# STM32U3B5xx register map
File version: 1.0
Registers are 32-bit, read-write, reset 0x0 unless marked. A register's access mark holds for its fields unless they carry their own. Offsets are from the block's base; [hi:lo] are bit positions; {n}, {i} and the like mark numbered series.

## PWR — Power Control
Base 0x40030800
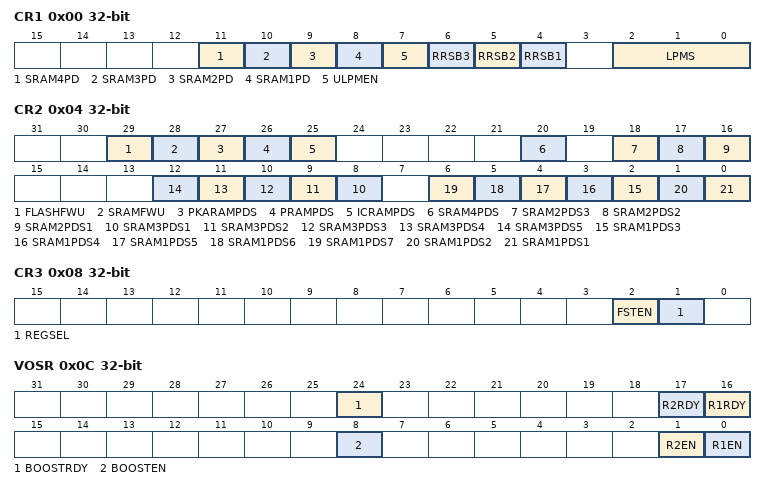
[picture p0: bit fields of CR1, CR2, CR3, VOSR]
0x00 CR1 — Power control register 1
  [11] SRAM4PD — SRAM4 (64 KB) power-down in Run mode
  [10] SRAM3PD — SRAM3 (320 KB) power-down in Run mode
  [9] SRAM2PD — SRAM2 (64 KB) power-down in Run mode
  [8] SRAM1PD — SRAM1 (192 KB) power-down in Run mode
  [7] ULPMEN — BOR ultra-low power mode in Standby/Shutdown
  [6] RRSB3 — SRAM2 page 3 Retention in Standby
  [5] RRSB2 — SRAM2 page 2 Retention in Standby
  [4] RRSB1 — SRAM2 page 1 Retention in Standby
  [2:0] LPMS — LPMS[2:0] Low-power mode selection field
    {v}=STOP{v} (Stop {v} mode) (v=0..3); 4=STANDBY (Standby mode); 6=SHUTDOWN (Shutdown mode)
0x04 CR2 — Power control register 2
  [29] FLASHFWU — Flash memory fast wakeup from Stop modes (Stop 0, 1)
  [28] SRAMFWU — SRAM fast wakeup from Stop modes (Stop 0, 1)
  [27] PKARAMPDS — PKA32 SRAM power-down in Stop modes (Stop 0, 1)
    0=NO_RETENTION (PKA SRAM no retention in Stop modes (Stop 0, 1, 2, 3)); 1=RETENTION
  [26] PRAMPDS — FDCAN and USB peripherals SRAM power-down in Stop modes (Stop 0, 1, 2, 3)
    0=NO_RETENTION; 1=RETENTION
  [25] ICRAMPDS — ICACHE SRAM power-down in Stop modes (Stop 0, 1, 2, 3)
    0=NO_RETENTION; 1=RETENTION
  [20] SRAM4PDS — SRAM4 (64 KB) power-down in Stop modes (Stop 0, 1, 2, 3)
  [18] SRAM2PDS3 — SRAM2 page 3 (32 KB) power-down in Stop modes (Stop 0, 1, 2, 3)
  [17] SRAM2PDS2 — SRAM2 page 2 (24 KB) power-down in Stop modes (Stop 0, 1, 2, 3)
  [16] SRAM2PDS1 — SRAM2 page 1 (8 KB) power-down in Stop modes (Stop 0, 1, 2, 3)
  [n+7] SRAM3PDS{n} (n=1..5) — SRAM3 page {n} (64 KB) power-down in Stop modes (Stop 0, 1, 2, 3)
  [n-1] SRAM1PDS{n} (n=3..7) — SRAM1 page {n} (32 KB) power-down in Stop modes (Stop 0, 1, 2, 3)
  [1] SRAM1PDS2 — SRAM1 page 2 (16 KB) power-down in Stop modes (Stop 0, 1, 2, 3)
  [0] SRAM1PDS1 — SRAM1 page 1 (16 KB) power-down in Stop modes (Stop 0, 1, 2, 3)
0x08 CR3 — Power control register 3
  [2] FSTEN — Fast soft start
  [1] REGSEL — Regulator selection
    0=LDO_SUPPLY (LDO regulator supply); 1=SMPS_SUPPLY (SMPS regulator supply)
0x0C VOSR — Power voltage scaling register
  [24] BOOSTRDY — EPOD booster ready
  [17] R2RDY — Ready bit for Vcore range 2 selection
  [16] R1RDY — Ready bit for Vcore range 1 selection
  [8] BOOSTEN — EPOD booster enable
  [1] R2EN — Voltage scaling range 2 selection
  [0] R1EN — Voltage scaling range 1 selection
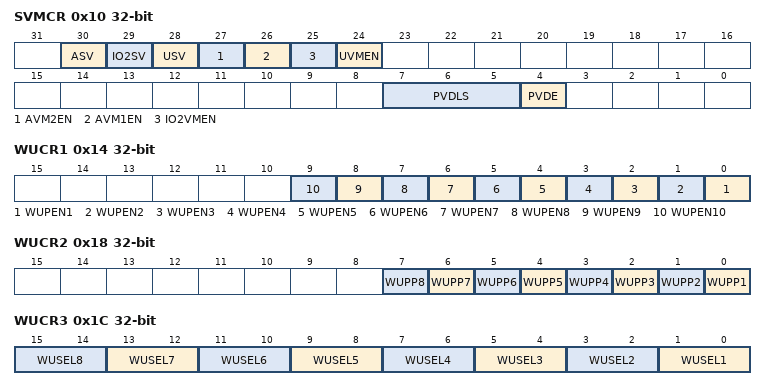
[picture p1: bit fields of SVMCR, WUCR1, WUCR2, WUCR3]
0x10 SVMCR — Power supply voltage monitoring control register
  [30] ASV — VDDA Independent analog supply valid
  [29] IO2SV — VDDIO2 Independent I/Os supply valid
  [28] USV — VDDUSB Independent USB supply valid
  [27] AVM2EN — VDDA Independent analog supply voltage monitor 2 enable
  [26] AVM1EN — VDDA Independent analog supply voltage monitor 1 enable
  [25] IO2VMEN — VDDIO2 Independent I/Os voltage monitor enable
  [24] UVMEN — VDDUSB Independent USB supply voltage monitor enable
  [7:5] PVDLS — PVDLS[2:0] Programmable voltage detector level selection field
    0=PVDLEVEL_0 (Voltage threshold detected by PVD 2.0 V); 1=PVDLEVEL_1 (Voltage threshold detected by PVD 2.2 V); 2=PVDLEVEL_2 (Voltage threshold detected by PVD 2.4 V); 3=PVDLEVEL_3 (Voltage threshold detected by PVD 2.5 V); 4=PVDLEVEL_4 (Voltage threshold detected by PVD 2.6 V); 5=PVDLEVEL_5 (Voltage threshold detected by PVD 2.8 V); 6=PVDLEVEL_6 (Voltage threshold detected by PVD 2.9 V); 7=PVDLEVEL_7
  [4] PVDE — Programmable voltage detector enable
0x14 WUCR1 — Power wakeup control register 1
  [n-1] WUPEN{n} (n=1..10) — Wakeup line WKUP{n} enable
0x18 WUCR2 — Power wakeup control register 2
  [n-1] WUPP{n} (n=1..8) — Wakeup line WKUP{n} polarity
0x1C WUCR3 — Power wakeup control register 3
  [2n-1:2n-2] WUSEL{n} (n=1..8) — Wakeup line WKUP{n} selection field
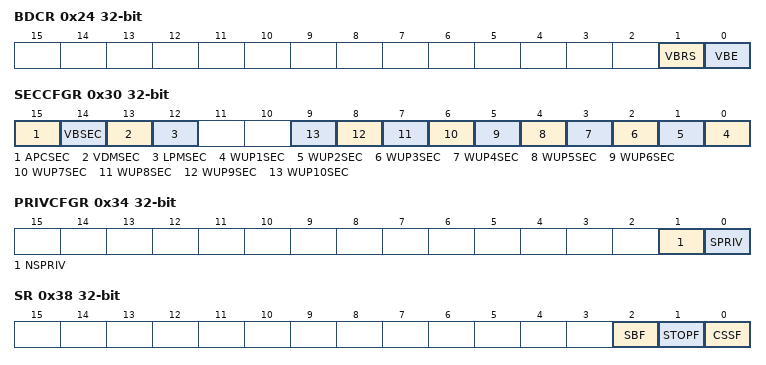
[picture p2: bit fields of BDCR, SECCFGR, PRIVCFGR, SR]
0x24 BDCR — Power backup domain control register
  [1] VBRS — VBAT charging resistor selection
    0=RESISTOR_5K (Charge the battery through a 5 kO resistor); 1=RESISTOR_1_5K (Charge the battery through a 1.5 kO resistor)
  [0] VBE — VBAT charging enable
0x28 DBPR — Power disable backup domain register
  [0] DBP — Disable backup domain write protection
0x30 SECCFGR — Power Security configuration register
  [15] APCSEC — Pull-up/pull-down secure protection
  [14] VBSEC — Backup domain secure protection
  [13] VDMSEC — Voltage detection and monitoring secure protection
  [12] LPMSEC — Low-power modes secure protection
  [n-1] WUP{n}SEC (n=1..10) — WUP{n} secure protection
0x34 PRIVCFGR — Power privilege control register
  [1] NSPRIV — PWR non-secure functions privilege configuration
  [0] SPRIV — PWR secure functions privilege configuration
0x38 SR — Power status register
  [2] SBF — Standby flag
  [1] STOPF — Stop flag
  [0] CSSF — Clear Stop and Standby/Shutdown flags
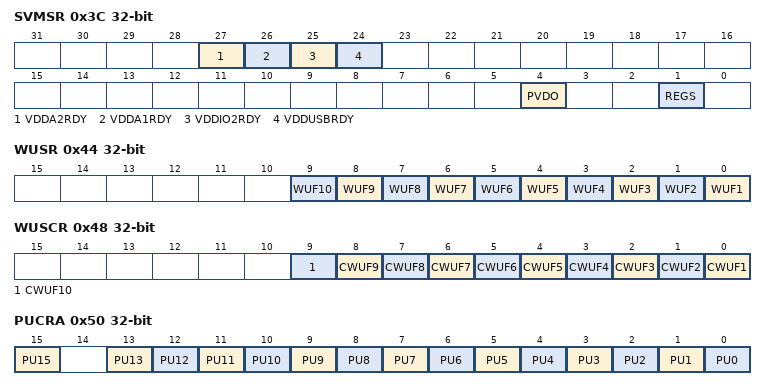
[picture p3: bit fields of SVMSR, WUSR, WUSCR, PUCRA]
0x3C SVMSR — Power supply voltage monitoring status register
  [27] VDDA2RDY — VDDA ready versus 1.8V voltage monitor
  [26] VDDA1RDY — VDDA ready versus 1.6V voltage monitor
  [25] VDDIO2RDY — VDDIO2 ready
  [24] VDDUSBRDY — VDDUSB ready
  [4] PVDO — VDD voltage detector output
  [1] REGS — Regulator status
0x44 WUSR — Power wakeup status register
  [n-1] WUF{n} (n=1..10) — Wakeup flag {n}
0x48 WUSCR — Power wakeup status clear register
  [n-1] CWUF{n} (n=1..10) — Wakeup clear flag {n}
0x4C APCR — Power apply pull configuration register
  [0] APC — Apply pull-up and pull-down configuration
0x50 PUCRA — Power Port A pull-up control register
  [15] PU15 — Apply pull-up for PA15
  [n] PU{n} (n=0..13) — Apply pull-up for PA{n}
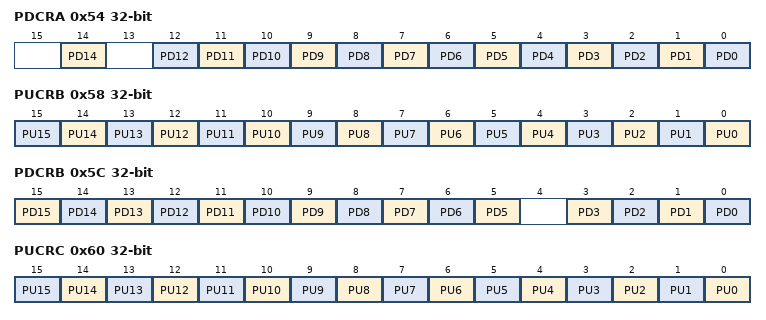
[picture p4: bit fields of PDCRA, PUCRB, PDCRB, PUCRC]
0x54 PDCRA — Power Port A pull-down control register
  [14] PD14 — Apply pull-down for PA14
  [n] PD{n} (n=0..12) — Apply pull-down for PA{n}
0x58 PUCRB — Power Port B pull-up control register
  [n] PU{n} (n=0..15) — Apply pull-up for PB{n}
0x5C PDCRB — Power Port B pull-down control register
  [n] PD{n} (n=5..15) — Apply pull-down for PB{n}
  [n] PD{n} (n=0..3) — Apply pull-down for PB{n}
0x60 PUCRC — Power Port C pull-up control register
  [n] PU{n} (n=0..15) — Apply pull-up for PC{n}
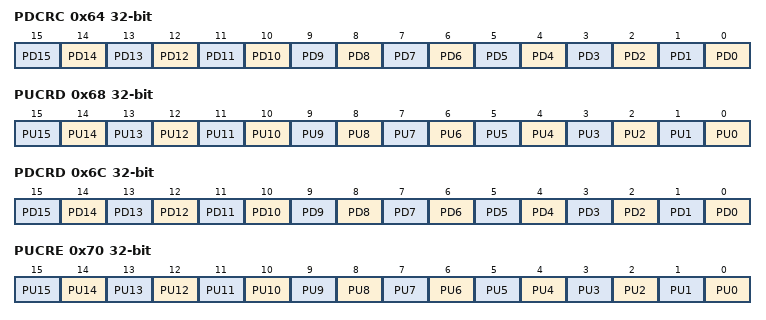
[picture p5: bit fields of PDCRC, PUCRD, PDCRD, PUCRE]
0x64 PDCRC — Power Port C pull-down control register
  [n] PD{n} (n=0..15) — Apply pull-down for PC{n}
0x68 PUCRD — Power Port D pull-up control register
  [n] PU{n} (n=0..15) — Apply pull-up for PD{n}
0x6C PDCRD — Power Port D pull-down control register
  [n] PD{n} (n=0..15) — Apply pull-down for PD{n}
0x70 PUCRE — Power Port E pull-up control register
  [n] PU{n} (n=0..15) — Apply pull-up for PE{n}
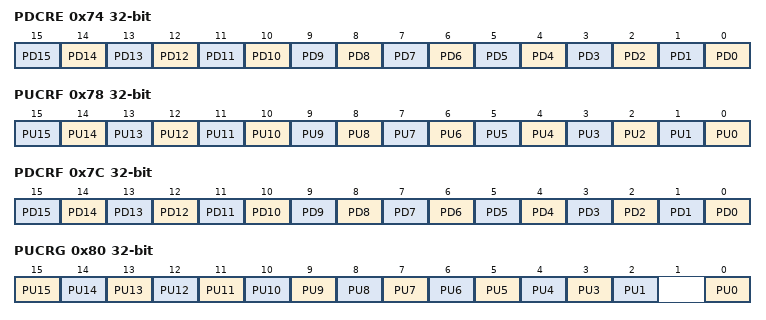
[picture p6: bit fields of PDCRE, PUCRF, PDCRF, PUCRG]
0x74 PDCRE — Power Port E pull-down control register
  [n] PD{n} (n=0..15) — Apply pull-down for PE{n}
0x78 PUCRF — Power Port F pull-up control register
  [n] PU{n} (n=0..15) — Apply pull-up for PF{n}
0x7C PDCRF — Power Port F pull-down control register
  [n] PD{n} (n=0..15) — Apply pull-down for PF{n}
0x80 PUCRG — Power Port G pull-up control register
  [n] PU{n} (n=3..15) — Apply pull-up for PG{n}
  [2] PU1 — Apply pull-up for PG1
  [0] PU0 — Apply pull-up for PG0
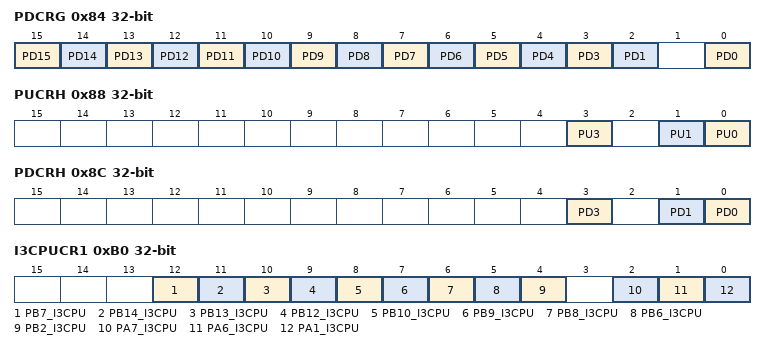
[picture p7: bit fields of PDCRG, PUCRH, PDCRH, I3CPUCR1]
0x84 PDCRG — Power Port G pull-down control register
  [n] PD{n} (n=3..15) — Apply pull-down for PG{n}
  [2] PD1 — Apply pull-down for PG1
  [0] PD0 — Apply pull-down for PG0
0x88 PUCRH — Power Port H pull-up control register
  [3] PU3 — Apply pull-up for PH3
  [1] PU1 — Apply pull-up for PH1
  [0] PU0 — Apply pull-up for PH0
0x8C PDCRH — Power Port H pull-down control register
  [3] PD3 — Apply pull-down for PH3
  [1] PD1 — Apply pull-down for PH1
  [0] PD0 — Apply pull-down for PH0
0xB0 I3CPUCR1 — Power I3C pull-up control register 1
  [12] PB7_I3CPU — Port B pin 7 I3C pull-up
  [11] PB14_I3CPU — Port B pin 14 I3C pull-up
  [10] PB13_I3CPU — Port B pin 13 I3C pull-up
  [9] PB12_I3CPU — Port B pin 12 I3C pull-up
  [8] PB10_I3CPU — Port B pin 10 I3C pull-up
  [7] PB9_I3CPU — Port B pin 9 I3C pull-up
  [6] PB8_I3CPU — Port B pin 8 I3C pull-up
  [5] PB6_I3CPU — Port B pin 6 I3C pull-up
  [4] PB2_I3CPU — Port B pin 2 I3C pull-up
  [2] PA7_I3CPU — Port A pin 7 I3C pull-up
  [1] PA6_I3CPU — Port A pin 6 I3C pull-up
  [0] PA1_I3CPU — Port A pin 1 I3C pull-up
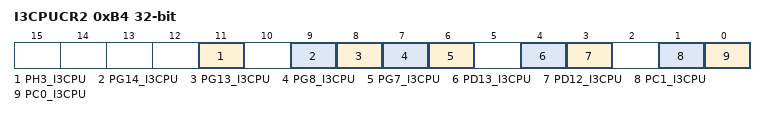
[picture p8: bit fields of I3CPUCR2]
0xB4 I3CPUCR2 — Power I3C pull-up control register 2
  [11] PH3_I3CPU — Port H pin 3 I3C pull-up
  [9] PG14_I3CPU — Port G pin 14 I3C pull-up
  [8] PG13_I3CPU — Port G pin 13 I3C pull-up
  [7] PG8_I3CPU — Port G pin 8 I3C pull-up
  [6] PG7_I3CPU — Port G pin 7 I3C pull-up
  [4] PD13_I3CPU — Port D pin 13 I3C pull-up
  [3] PD12_I3CPU — Port D pin 12 I3C pull-up
  [1] PC1_I3CPU — Port C pin 1 I3C pull-up
  [0] PC0_I3CPU — Port C pin 0 I3C pull-up
